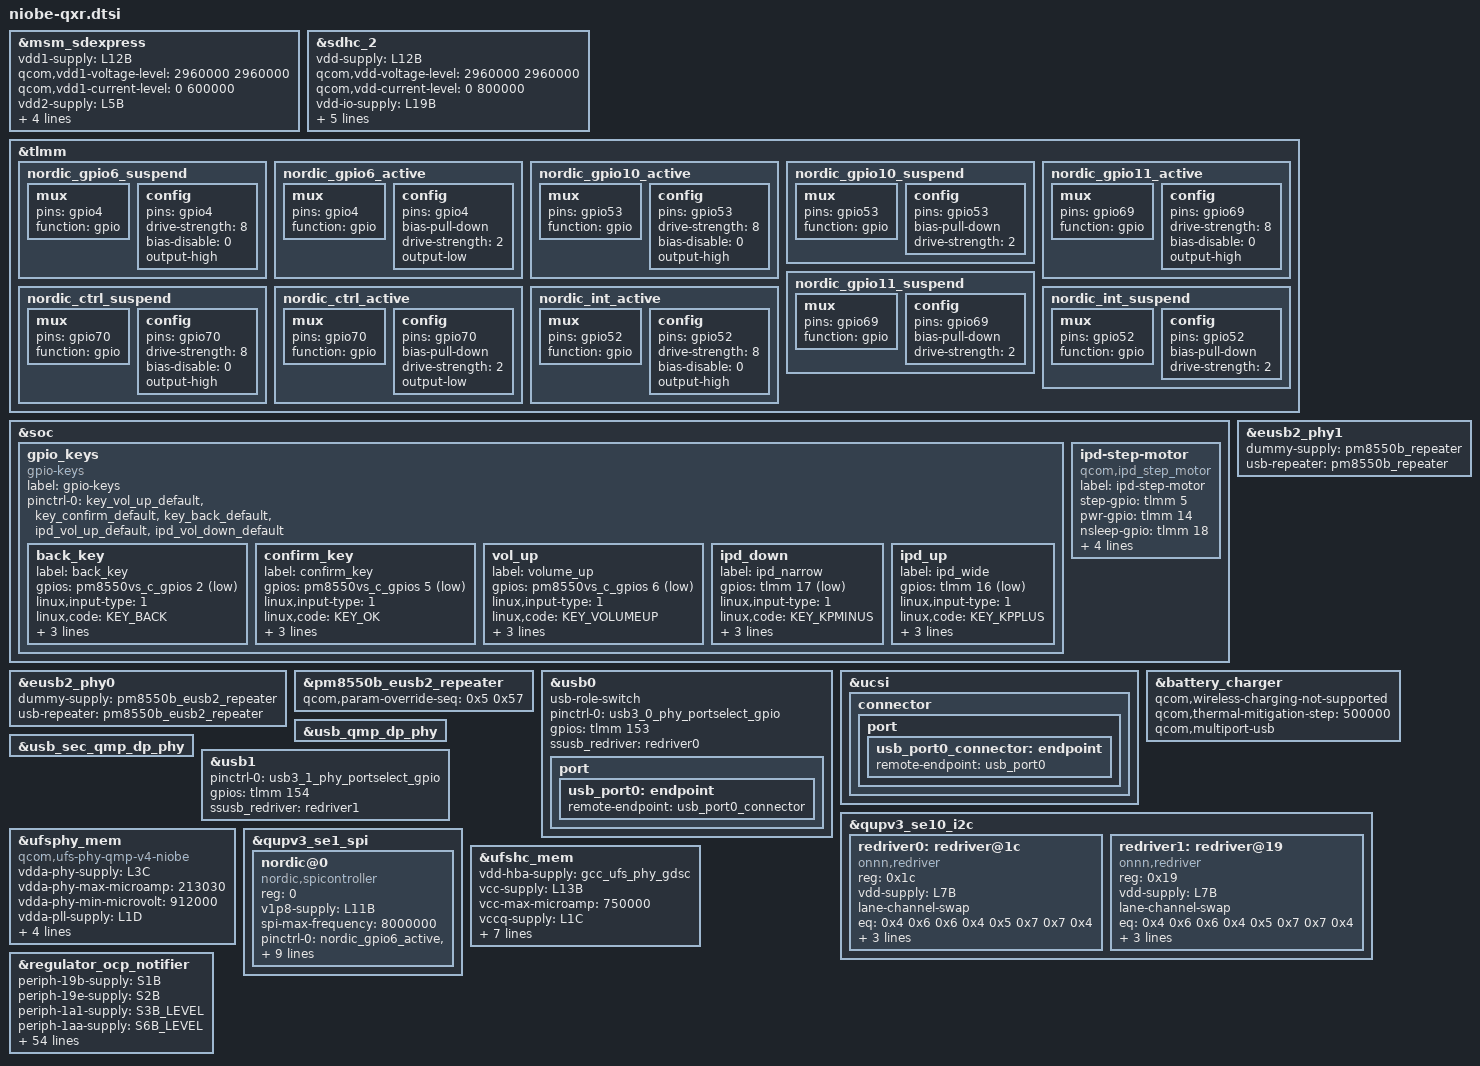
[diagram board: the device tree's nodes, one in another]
#include <dt-bindings/gpio/gpio.h>
#include <dt-bindings/input/input.h>

#include "niobe-pmic-overlay.dtsi"
#include "niobe-thermal-overlay.dtsi"

&msm_sdexpress {
	vdd1-supply = <&L12B>;
	qcom,vdd1-voltage-level = <2960000 2960000>;
	qcom,vdd1-current-level = <0 600000>;

	vdd2-supply = <&L5B>;
	qcom,vdd2-voltage-level = <1800000 1800000>;
	qcom,vdd2-current-level = <0 600000>;

	sdexpress-gpios = <&tlmm 71 0>;
	clkreq-gpios = <&tlmm 149 GPIO_ACTIVE_LOW>;

	status = "ok";
};

&sdhc_2 {
	status = "ok";

	vdd-supply = <&L12B>;
	qcom,vdd-voltage-level = <2960000 2960000>;
	qcom,vdd-current-level = <0 800000>;

	vdd-io-supply = <&L19B>;
	qcom,vdd-io-voltage-level = <1800000 2960000>;
	qcom,vdd-io-current-level = <0 22000>;

	pinctrl-names = "default", "sleep";
	pinctrl-0 = <&sdc2_on>;
	pinctrl-1 = <&sdc2_off>;

	cd-gpios = <&tlmm 148 GPIO_ACTIVE_LOW>;
};
&tlmm {
	nordic_gpio6_suspend: nordic_gpio6_suspend {
		mux {
			pins = "gpio4";
			function = "gpio";
		};

		config {
			pins = "gpio4";
			drive-strength = <8>;
			bias-disable = <0>;
			output-high;
		};
	};

	/* active low due to hmd nordic */
	nordic_gpio6_active: nordic_gpio6_active {
		mux {
			pins = "gpio4";
			function = "gpio";
		};

		config {
			pins = "gpio4";
			bias-pull-down; /* PULL DOWN */
			drive-strength = <2>; /* 2 MA */
			output-low;
		};
	};

	nordic_gpio10_active: nordic_gpio10_active {
		mux {
			pins = "gpio53";
			function = "gpio";
		};

		config {
			pins = "gpio53";
			drive-strength = <8>;
			bias-disable = <0>;
			output-high;
		};
	};

	nordic_gpio10_suspend: nordic_gpio10_suspend {
		mux {
			pins = "gpio53";
			function = "gpio";
		};

		config {
			pins = "gpio53";
			bias-pull-down; /* PULL DOWN */
			drive-strength = <2>; /* 2 MA */
		};
	};

	nordic_gpio11_active: nordic_gpio11_active {
		mux {
			pins = "gpio69";
			function = "gpio";
		};

		config {
			pins = "gpio69";
			drive-strength = <8>;
			bias-disable = <0>;
			output-high;
		};
	};

	nordic_gpio11_suspend: nordic_gpio11_suspend {
		mux {
			pins = "gpio69";
			function = "gpio";
		};

		config {
			pins = "gpio69";
			bias-pull-down; /* PULL DOWN */
			drive-strength = <2>; /* 2 MA */
		};
	};

	nordic_ctrl_suspend: nordic_ctrl_suspend {
		mux {
			pins = "gpio70";
			function = "gpio";
		};

		config {
			pins = "gpio70";
			drive-strength = <8>;
			bias-disable = <0>;
			output-high;
		};
	};

	/* active low due to hmd nordic */
	nordic_ctrl_active: nordic_ctrl_active {
		mux {
			pins = "gpio70";
			function = "gpio";
		};

		config {
			pins = "gpio70";
			bias-pull-down; /* PULL DOWN */
			drive-strength = <2>; /* 2 MA */
			output-low;
		};
	};

	nordic_int_active: nordic_int_active {
		mux {
			pins = "gpio52";
			function = "gpio";
		};

		config {
			pins = "gpio52";
			drive-strength = <8>;
			bias-disable = <0>;
			output-high;
		};
	};

	nordic_int_suspend: nordic_int_suspend {
		mux {
			pins = "gpio52";
			function = "gpio";
		};

		config {
			pins = "gpio52";
			bias-pull-down; /* PULL DOWN */
			drive-strength = <2>; /* 2 MA */
		};
	};
};

&soc {
	gpio_keys {
		compatible = "gpio-keys";
		label = "gpio-keys";

		pinctrl-names = "default";
		pinctrl-0 = <&key_vol_up_default
			     &key_confirm_default
			     &key_back_default
			     &ipd_vol_up_default
			     &ipd_vol_down_default>;

		back_key {
			label = "back_key";
			gpios = <&pm8550vs_c_gpios 2 GPIO_ACTIVE_LOW>;
			linux,input-type = <1>;
			linux,code = <KEY_BACK>;
			gpio-key,wakeup;
			debounce-interval = <15>;
			linux,can-disable;
		};

		confirm_key {
			label = "confirm_key";
			gpios = <&pm8550vs_c_gpios 5 GPIO_ACTIVE_LOW>;
			linux,input-type = <1>;
			linux,code = <KEY_OK>;
			gpio-key,wakeup;
			debounce-interval = <15>;
			linux,can-disable;
		};

		vol_up {
			label = "volume_up";
			gpios = <&pm8550vs_c_gpios 6 GPIO_ACTIVE_LOW>;
			linux,input-type = <1>;
			linux,code = <KEY_VOLUMEUP>;
			gpio-key,wakeup;
			debounce-interval = <15>;
			linux,can-disable;
		};

		ipd_down {
			label = "ipd_narrow";
			gpios = <&tlmm 17 GPIO_ACTIVE_LOW>;
			linux,input-type = <1>;
			linux,code = <KEY_KPMINUS>;
			gpio-key,wakeup;
			debounce-interval = <15>;
			linux,can-disable;
		};

		ipd_up {
			label = "ipd_wide";
			gpios = <&tlmm 16 GPIO_ACTIVE_LOW>;
			linux,input-type = <1>;
			linux,code = <KEY_KPPLUS>;
			gpio-key,wakeup;
			debounce-interval = <15>;
			linux,can-disable;
		};
	};

	ipd-step-motor {
		status = "ok";
		compatible = "qcom,ipd_step_motor";
		label = "ipd-step-motor";

		step-gpio = <&tlmm 5  0>;
		pwr-gpio = <&tlmm 14  0>;
		nsleep-gpio = <&tlmm 18  0>;
		nen-gpio = <&tlmm 72 0>;
		dir-gpio = <&tlmm  74 0>;

		io-channels = <&pmk8550_vadc PMXR2230_ADC5_GEN3_AMUX_THM5>;
		io-channel-names = "ipd_step_motor";
	};
};

&eusb2_phy0 {
	dummy-supply = <&pm8550b_eusb2_repeater>;
	usb-repeater = <&pm8550b_eusb2_repeater>;
};

&pm8550b_eusb2_repeater {
	qcom,param-override-seq =
		/* <value reg_offset> */
		/* Tx pre-emphasis tuning */
		<0x5 0x57>;
};

&eusb2_phy1 {
	dummy-supply = <&pm8550b_repeater>;
	usb-repeater = <&pm8550b_repeater>;
};

&usb0 {
	usb-role-switch;
	port {
		usb_port0: endpoint {
			remote-endpoint = <&usb_port0_connector>;
		};
	};
};

&ucsi {
	connector {
		port {
			usb_port0_connector: endpoint {
				remote-endpoint = <&usb_port0>;
			};
		};
	};
};

&battery_charger {
	qcom,wireless-charging-not-supported;
	qcom,thermal-mitigation-step = <500000>;
	#cooling-cells = <2>;
	qcom,multiport-usb;
};

&qupv3_se10_i2c {
	status = "ok";

	redriver0: redriver@1c {
		compatible = "onnn,redriver";
		reg = <0x1c>;

		vdd-supply = <&L7B>;

		lane-channel-swap;

		eq = /bits/ 8 <
				/* Parameters for USB */
				0x4 0x6 0x6 0x4
				/* Parameters for DP */
				0x5 0x7 0x7 0x4>;
		flat-gain = /bits/ 8 <
				/* Parameters for USB */
				0x3 0x3 0x3 0x3
				/* Parameters for DP */
				0x0 0x3 0x3 0x0>;
		output-comp = /bits/ 8 <
				/* Parameters for USB */
				0x3 0x3 0x3 0x3
				/* Parameters for DP */
				0x3 0x3 0x3 0x3>;
		loss-match = /bits/ 8 <
				/* Parameters for USB */
				0x1 0x3 0x3 0x1
				/* Parameters for DP */
				0x2 0x2 0x2 0x2>;
	};

	redriver1: redriver@19 {
		compatible = "onnn,redriver";
		reg = <0x19>;

		vdd-supply = <&L7B>;

		lane-channel-swap;

		eq = /bits/ 8 <
				/* Parameters for USB */
				0x4 0x6 0x6 0x4
				/* Parameters for DP */
				0x5 0x7 0x7 0x4>;
		flat-gain = /bits/ 8 <
				/* Parameters for USB */
				0x3 0x3 0x3 0x3
				/* Parameters for DP */
				0x0 0x3 0x3 0x0>;
		output-comp = /bits/ 8 <
				/* Parameters for USB */
				0x3 0x3 0x3 0x3
				/* Parameters for DP */
				0x3 0x3 0x3 0x3>;
		loss-match = /bits/ 8 <
				/* Parameters for USB */
				0x1 0x3 0x3 0x1
				/* Parameters for DP */
				0x2 0x2 0x2 0x2>;
	};


};

&usb_qmp_dp_phy {
	pinctrl-names = "unused";
};

&usb_sec_qmp_dp_phy {
	pinctrl-names = "unused";
};

&usb0 {
	pinctrl-names = "default";
	pinctrl-0 = <&usb3_0_phy_portselect_gpio>;
	gpios = <&tlmm 153 0>;

	ssusb_redriver = <&redriver0>;
};

&usb1 {
	pinctrl-names = "default";
	pinctrl-0 = <&usb3_1_phy_portselect_gpio>;
	gpios = <&tlmm 154 0>;

	ssusb_redriver = <&redriver1>;
};

&ufsphy_mem {
	compatible = "qcom,ufs-phy-qmp-v4-niobe";

	/* VDDA_UFS_CORE */
	vdda-phy-supply = <&L3C>;
	vdda-phy-max-microamp = <213030>;
	/*
	 * Platforms supporting Gear 5 && Rate B require a different
	 * voltage supply. Check the Power Grid document.
	 */
	vdda-phy-min-microvolt = <912000>;

	/* VDDA_UFS_0_1P2 */
	vdda-pll-supply = <&L1D>;
	vdda-pll-max-microamp =	<18310>;

	/* Phy GDSC for VDD_MX, always on */
	vdd-phy-gdsc-supply = <&gcc_ufs_mem_phy_gdsc>;

	/* Qref power supply, Refer Qref diagram */
	vdda-qref-supply = <&L1F>;
	vdda-qref-max-microamp = <4250>;

	status = "ok";
};

&qupv3_se1_spi {
	status = "okay";

	nordic@0 {
		compatible = "nordic,spicontroller";
		reg = <0>;

		v1p8-supply = <&L11B>;
		spi-max-frequency = <8000000>;
		pinctrl-names = "nordic_default", "nordic_sleep";
		pinctrl-0 = <&nordic_gpio6_active &nordic_ctrl_active>;
		pinctrl-1 = <&nordic_gpio6_suspend &nordic_ctrl_suspend>;

		nordic,ledl-gpio = <&tlmm 70 0>;
		nordic,ledr-gpio = <&tlmm 4 0>;

		interrupt-parent = <&tlmm>;
		interrupt-names = "nordicspi_irq";
		nordic,irq-gpio = <&tlmm 52 0>;
		nordic,irq_pin = <&tlmm 52 0x00>;
		interrupts = <52 1>;
	};
};

&ufshc_mem {
	vdd-hba-supply = <&gcc_ufs_phy_gdsc>;

	vcc-supply = <&L13B>;
	vcc-max-microamp = <750000>;

	vccq-supply = <&L1C>;
	vccq-max-microamp = <560000>;

	/* VDD_PX10 is voted for the ufs_reset_n */
	qcom,vddp-ref-clk-supply = <&L3B>;
	qcom,vddp-ref-clk-max-microamp = <100>;

	qcom,vccq-parent-supply = <&S2B>;
	qcom,vccq-parent-max-microamp = <210000>;

	qcom,vccq-shutdown-supply = <&L1C>;
	qcom,vccq-shutdown-max-microamp = <560000>;

	status = "ok";
};

&regulator_ocp_notifier {
	status = "ok";
	periph-19b-supply = <&S1B>;
	periph-19e-supply = <&S2B>;
	periph-1a1-supply = <&S3B_LEVEL>;
	periph-1aa-supply = <&S6B_LEVEL>;
	periph-1c1-supply = <&L1B>;
	periph-1c3-supply = <&L3B>;
	periph-1c4-supply = <&L4B>;
	periph-1c5-supply = <&L5B>;
	periph-1c6-supply = <&L6B>;
	periph-1c7-supply = <&L7B>;
	periph-1c8-supply = <&L8B>;
	periph-1c9-supply = <&L9B>;
	periph-1ca-supply = <&L10B>;
	periph-1cb-supply = <&L11B>;
	periph-1cc-supply = <&L12B>;
	periph-1cd-supply = <&L13B>;
	periph-1ce-supply = <&L14B>;
	periph-1cf-supply = <&L15B>;
	periph-1d0-supply = <&L16B>;
	periph-1d3-supply = <&L19B>;
	periph-1d6-supply = <&L22B>;
	periph-1d7-supply = <&L23B>;
	periph-1e4-supply = <&BOB1>;
	periph-29b-supply = <&S1C_LEVEL>;
	periph-29e-supply = <&S2C_LEVEL>;
	periph-2a4-supply = <&S4C_LEVEL>;
	periph-2a1-supply = <&S3C>;
	periph-2c1-supply = <&L1C>;
	periph-2c3-supply = <&L3C>;
	periph-39b-supply = <&S1D_LEVEL>;
	periph-3a1-supply = <&S3D_LEVEL>;
	periph-3a4-supply = <&S4D_LEVEL>;
	periph-3a7-supply = <&S5D>;
	periph-3aa-supply = <&S6D>;
	periph-3c1-supply = <&L1D>;
	periph-3c2-supply = <&L2D>;
	periph-3c3-supply = <&L3D>;
	periph-5a1-supply = <&S3F_LEVEL>;
	periph-5a4-supply = <&S4F>;
	periph-5a7-supply = <&S5F>;
	periph-5aa-supply = <&S6F_LEVEL>;
	periph-5c1-supply = <&L1F>;
	periph-5c2-supply = <&L2F_LEVEL>;
	periph-5c3-supply = <&L3F_LEVEL>;
	periph-c40-supply = <&L1M>;
	periph-c41-supply = <&L2M>;
	periph-c42-supply = <&L3M>;
	periph-c43-supply = <&L4M>;
	periph-c44-supply = <&L5M>;
	periph-c45-supply = <&L6M>;
	periph-c46-supply = <&L7M>;
	periph-d40-supply = <&L1N>;
	periph-d41-supply = <&L2N>;
	periph-d42-supply = <&L3N>;
	periph-d43-supply = <&L4N>;
	periph-d44-supply = <&L5N>;
	periph-d45-supply = <&L6N>;
	periph-d46-supply = <&L7N>;
};
